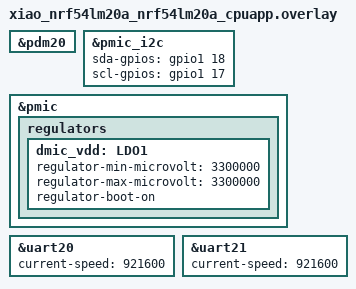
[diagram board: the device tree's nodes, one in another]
dmic_dev: &pdm20 {
	status = "okay";
};

&pmic_i2c {
	sda-gpios = <&gpio1 18 GPIO_ACTIVE_HIGH>;
	scl-gpios = <&gpio1 17 GPIO_ACTIVE_HIGH>;
	status = "okay";
};

&pmic {
	regulators {
		dmic_vdd: LDO1 {
			regulator-min-microvolt = <3300000>;
			regulator-max-microvolt = <3300000>;
			regulator-boot-on;
		};
	};
};

&uart20 {
	current-speed = <921600>;
};

&uart21 {
	current-speed = <921600>;
};
